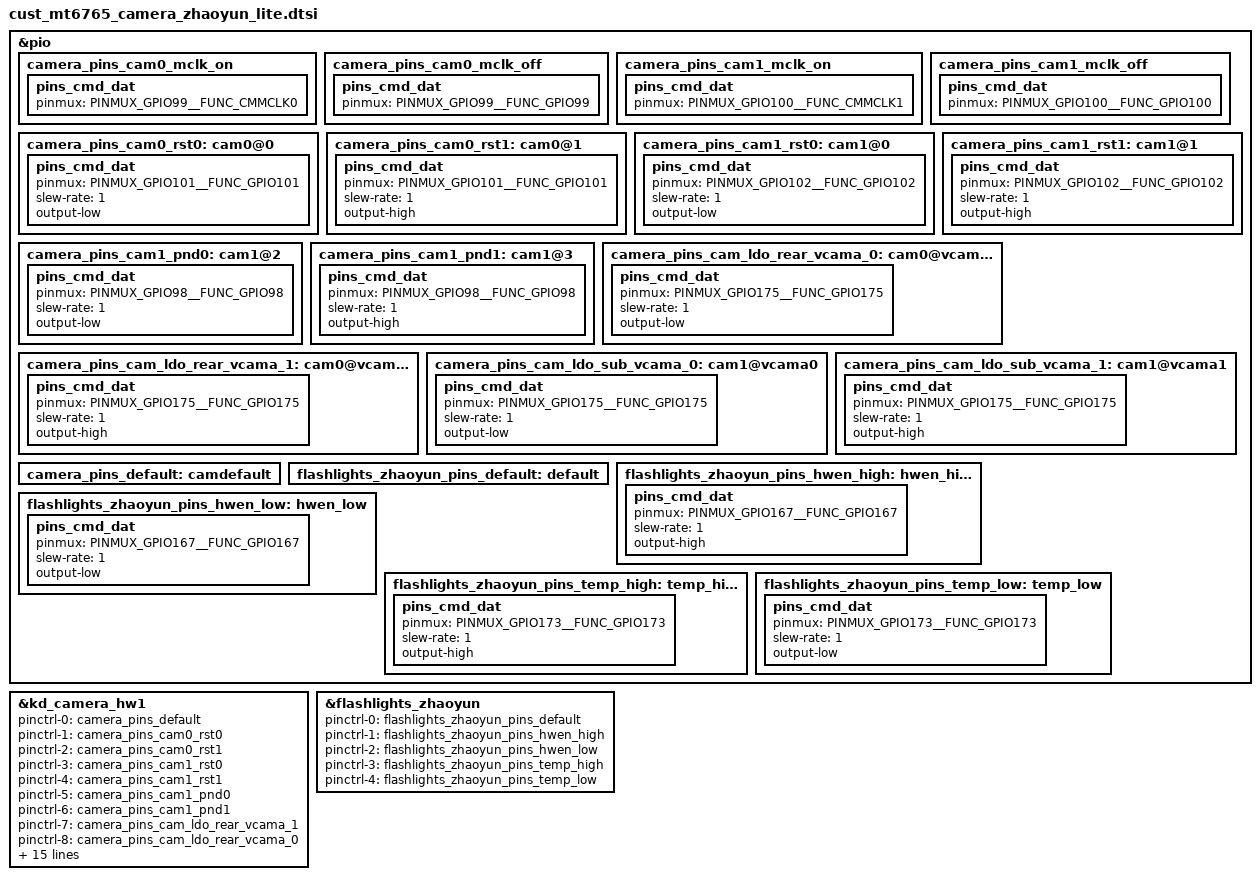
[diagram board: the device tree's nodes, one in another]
// SPDX-License-Identifier: GPL-2.0+
/*
 * Copyright (c) 2019 MediaTek Inc.
 *
 */

/* CAMERA GPIO standardization */
&pio {
	camera_pins_cam0_mclk_on: camera_pins_cam0_mclk_on {
		pins_cmd_dat {
			pinmux = <PINMUX_GPIO99__FUNC_CMMCLK0>;
		};
	};
	camera_pins_cam0_mclk_off: camera_pins_cam0_mclk_off {
		pins_cmd_dat {
			pinmux = <PINMUX_GPIO99__FUNC_GPIO99>;
		};
	};
	camera_pins_cam1_mclk_on: camera_pins_cam1_mclk_on {
		pins_cmd_dat {
			pinmux = <PINMUX_GPIO100__FUNC_CMMCLK1>;
		};
	};
	camera_pins_cam1_mclk_off: camera_pins_cam1_mclk_off {
		pins_cmd_dat {
			pinmux = <PINMUX_GPIO100__FUNC_GPIO100>;
		};
	};
	camera_pins_cam0_rst0: cam0@0 {
		pins_cmd_dat {
			pinmux = <PINMUX_GPIO101__FUNC_GPIO101>;
			slew-rate = <1>;
			output-low;
		};
	};
	camera_pins_cam0_rst1: cam0@1 {
		pins_cmd_dat {
			pinmux = <PINMUX_GPIO101__FUNC_GPIO101>;
			slew-rate = <1>;
			output-high;
		};
	};
	camera_pins_cam1_rst0: cam1@0 {
		pins_cmd_dat {
			pinmux = <PINMUX_GPIO102__FUNC_GPIO102>;
			slew-rate = <1>;
			output-low;
		};
	};
	camera_pins_cam1_rst1: cam1@1 {
		pins_cmd_dat {
			pinmux = <PINMUX_GPIO102__FUNC_GPIO102>;
			slew-rate = <1>;
			output-high;
		};
	};
	camera_pins_cam1_pnd0: cam1@2 {
		pins_cmd_dat {
			pinmux = <PINMUX_GPIO98__FUNC_GPIO98>;
			slew-rate = <1>;
			output-low;
		};
	};
	camera_pins_cam1_pnd1: cam1@3 {
		pins_cmd_dat {
			pinmux = <PINMUX_GPIO98__FUNC_GPIO98>;
			slew-rate = <1>;
			output-high;
		};
	};
	camera_pins_cam_ldo_rear_vcama_0: cam0@vcama0 {
		pins_cmd_dat {
			pinmux = <PINMUX_GPIO175__FUNC_GPIO175>;
			slew-rate = <1>;
			output-low;
		};
	};
	camera_pins_cam_ldo_rear_vcama_1: cam0@vcama1 {
		pins_cmd_dat {
			pinmux = <PINMUX_GPIO175__FUNC_GPIO175>;
			slew-rate = <1>;
			output-high;
		};
	};
	camera_pins_cam_ldo_sub_vcama_0: cam1@vcama0 {
		pins_cmd_dat {
			pinmux = <PINMUX_GPIO175__FUNC_GPIO175>;
			slew-rate = <1>;
			output-low;
		};
	};
	camera_pins_cam_ldo_sub_vcama_1: cam1@vcama1 {
		pins_cmd_dat {
			pinmux = <PINMUX_GPIO175__FUNC_GPIO175>;
			slew-rate = <1>;
			output-high;
		};
	};
	camera_pins_default: camdefault {
	};

};

&kd_camera_hw1 {
	pinctrl-names = "default",
			"cam0_rst0",
			"cam0_rst1",
			"cam1_rst0",
			"cam1_rst1",
			"cam1_pnd0",
			"cam1_pnd1",
			"cam0_vcama_on",
			"cam0_vcama_off",
			"cam1_vcama_on",
			"cam1_vcama_off",
			"cam0_mclk_on",
			"cam0_mclk_off",
			"cam1_mclk_on",
			"cam1_mclk_off";

	pinctrl-0 = <&camera_pins_default>;
	pinctrl-1 = <&camera_pins_cam0_rst0>;
	pinctrl-2 = <&camera_pins_cam0_rst1>;
	pinctrl-3 = <&camera_pins_cam1_rst0>;
	pinctrl-4 = <&camera_pins_cam1_rst1>;
	pinctrl-5 = <&camera_pins_cam1_pnd0>;
	pinctrl-6 = <&camera_pins_cam1_pnd1>;
	pinctrl-7 = <&camera_pins_cam_ldo_rear_vcama_1>;
	pinctrl-8 = <&camera_pins_cam_ldo_rear_vcama_0>;
	pinctrl-9 = <&camera_pins_cam_ldo_sub_vcama_1>;
	pinctrl-10 = <&camera_pins_cam_ldo_sub_vcama_0>;
	pinctrl-11 = <&camera_pins_cam0_mclk_on>;
	pinctrl-12 = <&camera_pins_cam0_mclk_off>;
	pinctrl-13 = <&camera_pins_cam1_mclk_on>;
	pinctrl-14 = <&camera_pins_cam1_mclk_off>;

	cam0_vcamd-supply = <&mt_pmic_vcamd_ldo_reg>;//main dvdd
	cam0_vcamaf-supply = <&mt_pmic_vldo28_ldo_reg>;//main af
	cam0_vcamio-supply = <&mt_pmic_vcamio_ldo_reg>;//main iovdd
	cam1_vcamd-supply = <&mt_pmic_vcamd_ldo_reg>;//front dvdd
	cam1_vcamio-supply = <&mt_pmic_vcamio_ldo_reg>;//front iovdd

	cam0_enable_sensor = "zhaoyunlite_qtech_main_ov13b10 zhaoyun_shinetech_main_s5k3l6 zhaoyunlite_qtech_main_s5k3l6";
	cam1_enable_sensor = "zhaoyun_optics_front_gc5035";
	status = "okay";

};

&flashlights_zhaoyun {
	pinctrl-names = "zhaoyun_default",
			"zhaoyun_hwen_high",
			"zhaoyun_hwen_low",
			"zhaoyun_temp_high",
			"zhaoyun_temp_low";
	pinctrl-0 = <&flashlights_zhaoyun_pins_default>;
	pinctrl-1 = <&flashlights_zhaoyun_pins_hwen_high>;
	pinctrl-2 = <&flashlights_zhaoyun_pins_hwen_low>;
	pinctrl-3 = <&flashlights_zhaoyun_pins_temp_high>;
	pinctrl-4 = <&flashlights_zhaoyun_pins_temp_low>;
	status = "okay";
};

&pio {
	flashlights_zhaoyun_pins_default:default {
		};
	flashlights_zhaoyun_pins_hwen_high: hwen_high {
		pins_cmd_dat {
			pinmux = <PINMUX_GPIO167__FUNC_GPIO167>;
			slew-rate = <1>;
			output-high;
		};
	};
	flashlights_zhaoyun_pins_hwen_low: hwen_low {
		pins_cmd_dat {
			pinmux = <PINMUX_GPIO167__FUNC_GPIO167>;
			slew-rate = <1>;
			output-low;
		};
	};
	flashlights_zhaoyun_pins_temp_high: temp_high {
		pins_cmd_dat {
			pinmux = <PINMUX_GPIO173__FUNC_GPIO173>;
			slew-rate = <1>;
			output-high;
		};
	};
	flashlights_zhaoyun_pins_temp_low: temp_low {
		pins_cmd_dat {
			pinmux = <PINMUX_GPIO173__FUNC_GPIO173>;
			slew-rate = <1>;
			output-low;
		};
	};
};
/* CAMERA GPIO end */
